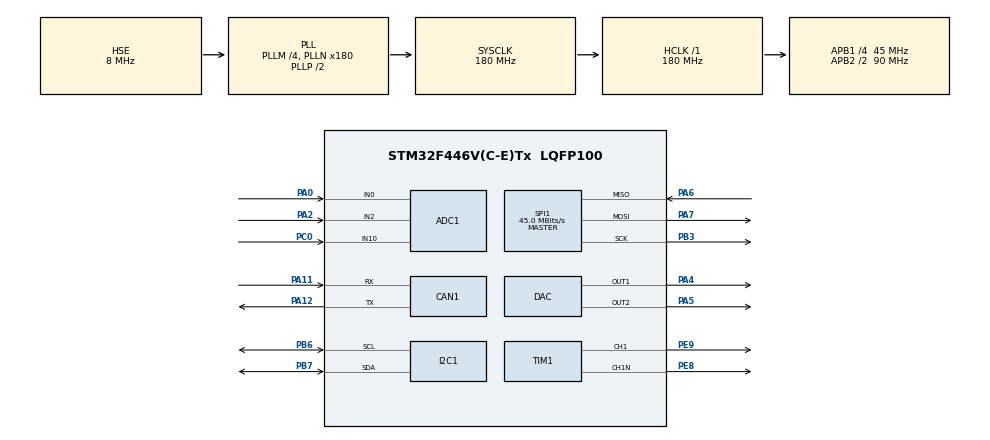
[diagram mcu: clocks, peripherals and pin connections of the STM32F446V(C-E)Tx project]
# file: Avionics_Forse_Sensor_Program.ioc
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ADC1.Channel-0\#ChannelRegularConversion=ADC_CHANNEL_0
ADC1.Channel-1\#ChannelRegularConversion=ADC_CHANNEL_2
ADC1.Channel-2\#ChannelRegularConversion=ADC_CHANNEL_10
ADC1.DiscontinuousConvMode=ENABLE
ADC1.NbrOfConversion=3
ADC1.NbrOfConversionFlag=1
ADC1.NbrOfDiscConversion=3
ADC1.Rank-0\#ChannelRegularConversion=1
ADC1.Rank-1\#ChannelRegularConversion=2
ADC1.Rank-2\#ChannelRegularConversion=3
ADC1.SamplingTime-0\#ChannelRegularConversion=ADC_SAMPLETIME_3CYCLES
ADC1.SamplingTime-1\#ChannelRegularConversion=ADC_SAMPLETIME_3CYCLES
ADC1.SamplingTime-2\#ChannelRegularConversion=ADC_SAMPLETIME_3CYCLES
ADC1.ScanConvMode=ENABLE
ADC1.master=1
CAN1.CalculateTimeBit=1066
CAN1.CalculateTimeQuantum=355.55555555555554
Mcu.Family=STM32F4
Mcu.Name=STM32F446V(C-E)Tx
Mcu.Package=LQFP100
NVIC.PriorityGroup=NVIC_PRIORITYGROUP_4
PA0-WKUP.Signal=ADCx_IN0
PA11.Mode=Master
PA11.Signal=CAN1_RX
PA12.Mode=Master
PA12.Signal=CAN1_TX
PA13.Mode=Serial_Wire
PA13.Signal=SYS_JTMS-SWDIO
PA14.Mode=Serial_Wire
PA14.Signal=SYS_JTCK-SWCLK
PA2.Signal=ADCx_IN2
PA4.Signal=COMP_DAC1_group
PA5.Signal=COMP_DAC2_group
PA6.Mode=Full_Duplex_Master
PA6.Signal=SPI1_MISO
PA7.Mode=Full_Duplex_Master
PA7.Signal=SPI1_MOSI
PB3.Mode=Full_Duplex_Master
PB3.Signal=SPI1_SCK
PB6.Mode=I2C
PB6.Signal=I2C1_SCL
PB7.Mode=I2C
PB7.Signal=I2C1_SDA
PC0.Signal=ADCx_IN10
PE8.Mode=Output Compare1 CH1 CH1N
PE8.Signal=TIM1_CH1N
PE9.Signal=S_TIM1_CH1
PH0-OSC_IN.Mode=HSE-External-Oscillator
PH0-OSC_IN.Signal=RCC_OSC_IN
PH1-OSC_OUT.Mode=HSE-External-Oscillator
PH1-OSC_OUT.Signal=RCC_OSC_OUT
ProjectManager.HeapSize=0x200
ProjectManager.StackSize=0x400
ProjectManager.TargetToolchain=TrueSTUDIO
RCC.AHBFreq_Value=180000000
RCC.APB1CLKDivider=RCC_HCLK_DIV4
RCC.APB1Freq_Value=45000000
RCC.APB1TimFreq_Value=90000000
RCC.APB2CLKDivider=RCC_HCLK_DIV2
RCC.APB2Freq_Value=90000000
RCC.APB2TimFreq_Value=180000000
RCC.CortexFreq_Value=180000000
RCC.HCLKFreq_Value=180000000
RCC.HSE_VALUE=8000000
RCC.PLLM=4
RCC.PLLN=180
RCC.PLLSourceVirtual=RCC_PLLSOURCE_HSE
RCC.SYSCLKFreq_VALUE=180000000
RCC.SYSCLKSource=RCC_SYSCLKSOURCE_PLLCLK
RCC.USBFreq_Value=180000000
RCC.VCOOutputFreq_Value=360000000
SH.ADCx_IN0.0=ADC1_IN0,IN0
SH.ADCx_IN10.0=ADC1_IN10,IN10
SH.ADCx_IN2.0=ADC1_IN2,IN2
SH.COMP_DAC1_group.0=DAC_OUT1,DAC_OUT1
SH.COMP_DAC2_group.0=DAC_OUT2,DAC_OUT2
SH.S_TIM1_CH1.0=TIM1_CH1,Output Compare1 CH1 CH1N
SPI1.CalculateBaudRate=45.0 MBits/s
SPI1.Direction=SPI_DIRECTION_2LINES
SPI1.Mode=SPI_MODE_MASTER
SPI1.VirtualType=VM_MASTER
TIM1.Channel-Output\ Compare1\ CH1\ CH1N=TIM_CHANNEL_1
board=Avionics_Forse_Sensor_Program

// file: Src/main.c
/**
  ******************************************************************************
  * File Name          : main.c
  * Description        : Main program body
  ******************************************************************************
  ** This notice applies to any and all portions of this file
  * that are not between comment pairs USER CODE BEGIN and
  * USER CODE END. Other portions of this file, whether
  * inserted by the user or by software development tools
  * are owned by their respective copyright owners.
  *
  * COPYRIGHT(c) 2018 STMicroelectronics
  *
  * Redistribution and use in source and binary forms, with or without modification,
  * are permitted provided that the following conditions are met:
  *   1. Redistributions of source code must retain the above copyright notice,
  *      this list of conditions and the following disclaimer.
  *   2. Redistributions in binary form must reproduce the above copyright notice,
  *      this list of conditions and the following disclaimer in the documentation
  *      and/or other materials provided with the distribution.
  *   3. Neither the name of STMicroelectronics nor the names of its contributors
  *      may be used to endorse or promote products derived from this software
  *      without specific prior written permission.
  *
  * THIS SOFTWARE IS PROVIDED BY THE COPYRIGHT HOLDERS AND CONTRIBUTORS "AS IS"
  * AND ANY EXPRESS OR IMPLIED WARRANTIES, INCLUDING, BUT NOT LIMITED TO, THE
  * IMPLIED WARRANTIES OF MERCHANTABILITY AND FITNESS FOR A PARTICULAR PURPOSE ARE
  * DISCLAIMED. IN NO EVENT SHALL THE COPYRIGHT HOLDER OR CONTRIBUTORS BE LIABLE
  * FOR ANY DIRECT, INDIRECT, INCIDENTAL, SPECIAL, EXEMPLARY, OR CONSEQUENTIAL
  * DAMAGES (INCLUDING, BUT NOT LIMITED TO, PROCUREMENT OF SUBSTITUTE GOODS OR
  * SERVICES; LOSS OF USE, DATA, OR PROFITS; OR BUSINESS INTERRUPTION) HOWEVER
  * CAUSED AND ON ANY THEORY OF LIABILITY, WHETHER IN CONTRACT, STRICT LIABILITY,
  * OR TORT (INCLUDING NEGLIGENCE OR OTHERWISE) ARISING IN ANY WAY OUT OF THE USE
  * OF THIS SOFTWARE, EVEN IF ADVISED OF THE POSSIBILITY OF SUCH DAMAGE.
  *
  ******************************************************************************
  */

#include "main.h"
#include "stm32f4xx_hal.h"
#include "adc.h"
#include "can.h"
#include "dac.h"
#include "i2c.h"
#include "spi.h"
#include "tim.h"
#include "gpio.h"

/* USER CODE BEGIN Includes */
extern ADC_HandleTypeDef hadc1;
/* USER CODE END Includes */

/* USER CODE BEGIN PV */
/* Private variables ---------------------------------------------------------*/

/* USER CODE END PV */

void SystemClock_Config(void);

/* USER CODE BEGIN PFP */
/* Private function prototypes -----------------------------------------------*/

/* USER CODE END PFP */

int main(void)
{

  /* MCU Configuration----------------------------------------------------------*/

  /* Reset of all peripherals, Initializes the Flash interface and the Systick. */
  HAL_Init();

  /* Configure the system clock */
  SystemClock_Config();

  /* Initialize all configured peripherals */
  MX_GPIO_Init();
  MX_ADC1_Init();
  MX_CAN1_Init();
  MX_DAC_Init();
  MX_I2C1_Init();
  MX_SPI1_Init();
  MX_TIM1_Init();

  /* Infinite loop */
  /* USER CODE BEGIN WHILE */

  while (1)
  {
	// Enable the ADC and start conversion
	HAL_ADC_Start(&hadc1);

	// Poll each of the force transducer outputs
	HAL_ADC_PollForConversion(&hadc1, HAL_MAX_DELAY);
	int CONV_1_MON = HAL_ADC_GetValue(&hadc1);
	HAL_ADC_PollForConversion(&hadc1, HAL_MAX_DELAY);
	int CONV_2_MON = HAL_ADC_GetValue(&hadc1);
	HAL_ADC_PollForConversion(&hadc1, HAL_MAX_DELAY);
	int CONV_3_MON = HAL_ADC_GetValue(&hadc1);

	// Disables the ADC and stop conversion
	HAL_ADC_Stop(&hadc1);

	HAL_Delay(10);

  /* USER CODE END WHILE */

  }

}

/** System Clock Configuration
*/
void SystemClock_Config(void)
{

  RCC_OscInitTypeDef RCC_OscInitStruct;
  RCC_ClkInitTypeDef RCC_ClkInitStruct;

    /**Configure the main internal regulator output voltage
    */
  __HAL_RCC_PWR_CLK_ENABLE();

  __HAL_PWR_VOLTAGESCALING_CONFIG(PWR_REGULATOR_VOLTAGE_SCALE1);

    /**Initializes the CPU, AHB and APB busses clocks
    */
  RCC_OscInitStruct.OscillatorType = RCC_OSCILLATORTYPE_HSE;
  RCC_OscInitStruct.HSEState = RCC_HSE_ON;
  RCC_OscInitStruct.PLL.PLLState = RCC_PLL_ON;
  RCC_OscInitStruct.PLL.PLLSource = RCC_PLLSOURCE_HSE;
  RCC_OscInitStruct.PLL.PLLM = 4;
  RCC_OscInitStruct.PLL.PLLN = 180;
  RCC_OscInitStruct.PLL.PLLP = RCC_PLLP_DIV2;
  RCC_OscInitStruct.PLL.PLLQ = 2;
  RCC_OscInitStruct.PLL.PLLR = 2;
  if (HAL_RCC_OscConfig(&RCC_OscInitStruct) != HAL_OK)
  {
    _Error_Handler(__FILE__, __LINE__);
  }

    /**Activate the Over-Drive mode
    */
  if (HAL_PWREx_EnableOverDrive() != HAL_OK)
  {
    _Error_Handler(__FILE__, __LINE__);
  }

    /**Initializes the CPU, AHB and APB busses clocks
    */
  RCC_ClkInitStruct.ClockType = RCC_CLOCKTYPE_HCLK|RCC_CLOCKTYPE_SYSCLK
                              |RCC_CLOCKTYPE_PCLK1|RCC_CLOCKTYPE_PCLK2;
  RCC_ClkInitStruct.SYSCLKSource = RCC_SYSCLKSOURCE_PLLCLK;
  RCC_ClkInitStruct.AHBCLKDivider = RCC_SYSCLK_DIV1;
  RCC_ClkInitStruct.APB1CLKDivider = RCC_HCLK_DIV4;
  RCC_ClkInitStruct.APB2CLKDivider = RCC_HCLK_DIV2;

  if (HAL_RCC_ClockConfig(&RCC_ClkInitStruct, FLASH_LATENCY_5) != HAL_OK)
  {
    _Error_Handler(__FILE__, __LINE__);
  }

    /**Configure the Systick interrupt time
    */
  HAL_SYSTICK_Config(HAL_RCC_GetHCLKFreq()/1000);

    /**Configure the Systick
    */
  HAL_SYSTICK_CLKSourceConfig(SYSTICK_CLKSOURCE_HCLK);

  /* SysTick_IRQn interrupt configuration */
  HAL_NVIC_SetPriority(SysTick_IRQn, 0, 0);
}

void _Error_Handler(char * file, int line)
{
  while(1)
  {
  }
}

/************************ (C) COPYRIGHT STMicroelectronics *****END OF FILE****/
